# CY8C5888LTI_LP097 register map
File version: 0.1
CY8C58LP
Registers are 8-bit, read-write, no defined reset value unless marked. A register's access mark holds for its fields unless they carry their own. Offsets are from the block's base; lines under a group give offsets from that group; [hi:lo] are bit positions; {n}, {i} and the like mark numbered series; 'fields as' and 'values as' point back to an identical list; <NAME> marks a mode.

## Memory map
0x00000000 PWM_Right_Front
0x00000000 PWM_Right_Rear
0x00000000 GPS_UART — UART
0x00000000 Decoder_Left
0x00000000 Decoder_Left_Cnt16
0x00000000 Decoder_Right
0x00000000 Decoder_Right_Cnt16
0x00000000 Timer_Channel_Right
0x00000000 PWM_Left_Front
0x00000000 FT232_UART — UART
0x00000000 ESP07_UART — UART
0x00000000 PWM_Left_Rear
0x00000000 I2C
0x00000000 Timer_Channel_Left
0x40006472 Direction_Left_Rear
0x4000647C Direction_Left_Front
0x4000647D Direction_Right_Front
0x4000657A Direction_Right_Rear

## Direction_Right_Front
Base 0x4000647D
0x00 Direction_Right_Front_CONTROL_REG

## Direction_Left_Rear
Base 0x40006472
Registers as Direction_Right_Front (with Direction_Right_Front read as Direction_Left_Rear).

## Direction_Left_Front
Base 0x4000647C
Registers as Direction_Right_Front (with Direction_Right_Front read as Direction_Left_Front).

## Direction_Right_Rear
Base 0x4000657A
Registers as Direction_Right_Front (with Direction_Right_Front read as Direction_Right_Rear).

## PWM_Right_Front
Base 0x00000000
0x400043A3 PWM_Right_Front_GLOBAL_ENABLE — PM.ACT.CFG
  [3:0] en_timer — Enable timer/counters.
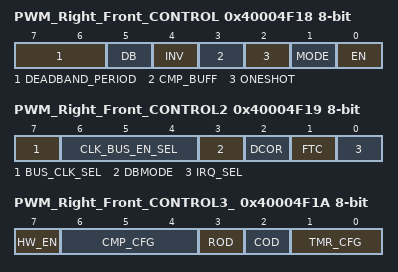
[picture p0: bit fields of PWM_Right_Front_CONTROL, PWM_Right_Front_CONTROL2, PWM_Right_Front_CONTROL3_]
0x40004F18 PWM_Right_Front_CONTROL — TMRx.CFG0
  [7:6] DEADBAND_PERIOD
  [5] DB — Deadband mode--Deadband phases phi1 and phi2 are outputted on CMP and TC output pins respectively.
    0=Timer (CMP and TC are output.); 1=Deadband (PHI1 (instead of CMP) and PHI2 (instead of TC) are output.)
  [4] INV — Invert sense of TIMEREN signal
  [3] CMP_BUFF — Buffer compare register. Compare register updates only on timer terminal count.
  [2] ONESHOT — Timer stops upon reaching stop condition defined by TMR_CFG bits. Can be restarted by asserting TIMER RESET or disabling and re-enabling block.
  [1] MODE — Mode. (0 = Timer; 1 = Comparator)
    0=Timer mode. CNT/CMP register holds timer count value.; 1=Comparator mode. CNT/CMP register holds comparator threshold value.
  [0] EN — Enables timer/comparator.
0x40004F19 PWM_Right_Front_CONTROL2 — TMRx.CFG1
  [7] BUS_CLK_SEL — Bus Clock selection.
  [6:4] CLK_BUS_EN_SEL — Digital Global Clock selection.
  [3] DBMODE — Deadband mode (asynchronous/synchronous). CMP output pin is also affected when not in deadband mode (CFG0.DEADBAND).
  [2] DCOR — Disable Clear on Read (DCOR) of Status Register SR0.
  [1] FTC — First Terminal Count (FTC). Setting this bit forces a single pulse on the TC pin when first enabled.
    0=Disable_FTC (Disable the single cycle pulse, which signifies the timer is starting.); 1=Enable_FTC (Enable the single cycle pulse, which signifies the timer is starting.)
  [0] IRQ_SEL — Irq selection. (0 = raw interrupts; 1 = status register interrupts)
0x40004F1A PWM_Right_Front_CONTROL3_ — TMRx.CFG2
  [7] HW_EN — When set Timer Enable controls counting.
  [6:4] CMP_CFG — Comparator configurations
    0=Equal (Compare Equal); 1=Less_than (Compare Less Than); 2=Less_than_or_equal (Compare Less Than or Equal .); 3=Greater (Compare Greater Than .); 4=Greater_than_or_equal (Compare Greater Than or Equal)
  [3] ROD — Reset On Disable (ROD). Resets internal state of output logic
  [2] COD — Clear On Disable (COD). Clears or gates outputs to zero.
  [1:0] TMR_CFG — Timer configuration (MODE = 0): 000 = Continuous; 001 = Pulsewidth; 010 = Period; 011 = Stop on IRQ
    0=Continuous (Timer runs while EN bit of CFG0 register is set to '1'.); 1=Pulsewidth (Timer runs from positive to negative edge of TIMEREN.); 2=Period (Timer runs from positive to positive edge of TIMEREN.); 3=Irq (Timer runs until IRQ.)
0x40004F1C PWM_Right_Front_PERIOD — TMRx.PER0 - Assigned Period
0x40004F1E PWM_Right_Front_COMPARE — TMRx.CNT_CMP0 - Assigned Compare Value
